# CBASS_AC_NONSAFE0_ISC register map
Vendor: Texas Instruments
Peripheral module from a debugger description file (folder J721S2).
Registers are 32-bit, read-write, reset 0x0 unless marked. A register's access mark holds for its fields unless they carry their own. Offsets are as the file gives them; lines under a group give offsets from that group; [hi:lo] are bit positions; {n}, {i} and the like mark numbered series; 'fields as' and 'values as' point back to an identical list; <NAME> marks a mode.

## CBASS_AC_NONSAFE0_ISC
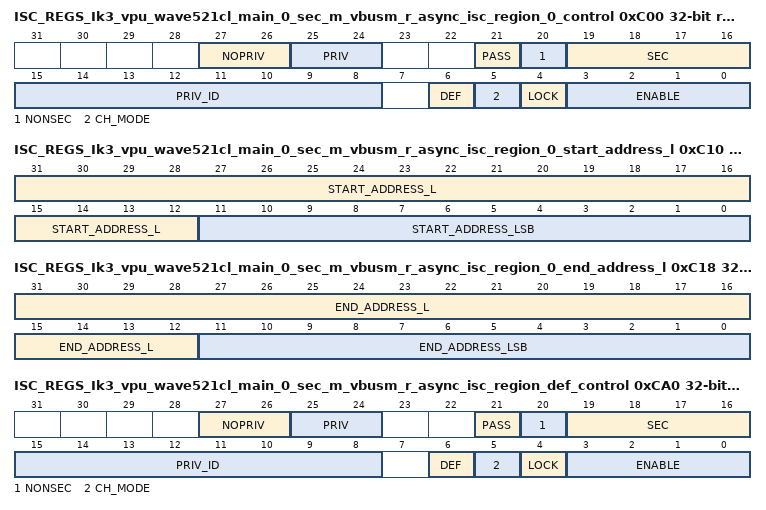
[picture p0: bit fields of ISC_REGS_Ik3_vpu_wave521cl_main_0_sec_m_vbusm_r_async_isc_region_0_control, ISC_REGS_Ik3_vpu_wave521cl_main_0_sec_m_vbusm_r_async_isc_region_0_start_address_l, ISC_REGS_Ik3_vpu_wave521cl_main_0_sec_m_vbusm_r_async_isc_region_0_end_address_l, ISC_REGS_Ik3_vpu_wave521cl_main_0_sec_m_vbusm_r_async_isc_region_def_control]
{0xC00+0x20*i} ISC_REGS_Ik3_vpu_wave521cl_main_0_sec_m_vbusm_r_async_isc_region_{i}_control access not given reset 0xBE00 (i=0..4) — The ISC Region {i} Control Register defines the control fields for the master Ik3_vpu_wave521cl_main_0.sec_m_vbusm_r_async region {i} ISC.
  [27:26] NOPRIV rw — Clear output priv attribute. If each bit is set then the outgoing priv bit is cleared.
  [25:24] PRIV rw — Set outgoing priv attribute. If each bit is set then the outgoing priv bit is set.
  [21] PASS rw — No privID replacement, pass through value.
  [20] NONSEC rw — Make outgoing non-secure.
  [19:16] SEC rw — Make outgoing secure. A value of 0xA enables, others disable.
  [15:8] PRIV_ID rw
  [6] DEF ro — Default region indication. The default region is used when all other regions do not match.
  [5] CH_MODE rw — Enable channel mode to match region to a chanid value. Otherwise use address mode to match region to an address range.
  [4] LOCK — Lock region. Once set the region values cannot be modified. (access R/W1TS)
  [3:0] ENABLE rw — Enable region. A value of 0xA enables, others disable.
{0xC10+0x20*i} ISC_REGS_Ik3_vpu_wave521cl_main_0_sec_m_vbusm_r_async_isc_region_{i}_start_address_l (i=0..4) — The ISC Region {i} Start Address Low Register defines the start address bits 31 to 0 for the master Ik3_vpu_wave521cl_main_0.sec_m_vbusm_r_async region {i} ISC.
  [31:12] START_ADDRESS_L — Start address bits 31 to 12.
  [11:0] START_ADDRESS_LSB — Start address bits 11 to 0 must be 0 as address must be 4KB aligned in address mode. Can also be channel number in channel mode.
{0xC14+0x20*i} ISC_REGS_Ik3_vpu_wave521cl_main_0_sec_m_vbusm_r_async_isc_region_{i}_start_address_h (i=0..4) — The ISC Region {i} Start Address High Register defines the start address bits 47 to 32 for the master Ik3_vpu_wave521cl_main_0.sec_m_vbusm_r_async region {i} ISC.
  [15:0] START_ADDRESS_H — Start address bits 47 to 32.
{0xC18+0x20*i} ISC_REGS_Ik3_vpu_wave521cl_main_0_sec_m_vbusm_r_async_isc_region_{i}_end_address_l access per field reset 0xFFF (i=0..4) — The ISC Region {i} End Address Low Register defines the end included address bits 31 to 0 for the master Ik3_vpu_wave521cl_main_0.sec_m_vbusm_r_async region {i} ISC.
  [31:12] END_ADDRESS_L rw — End address bits 31 to 12 to include in the match.
  [11:0] END_ADDRESS_LSB ro — End address bits 11 to 0 are forced to Fs as address must be 4KB aligned.
{0xC1C+0x20*i} ISC_REGS_Ik3_vpu_wave521cl_main_0_sec_m_vbusm_r_async_isc_region_{i}_end_address_h (i=0..4) — The ISC Region {i} End Address High Register defines the end address bits 47 to 32 for the master Ik3_vpu_wave521cl_main_0.sec_m_vbusm_r_async region {i} ISC.
  [15:0] END_ADDRESS_H — End address bits 47 to 32.
0xCA0 ISC_REGS_Ik3_vpu_wave521cl_main_0_sec_m_vbusm_r_async_isc_region_def_control access not given reset 0xBE4A — The ISC Default Region Control Register defines the control fields for the master Ik3_vpu_wave521cl_main_0.sec_m_vbusm_r_async region 5 ISC.
  [27:26] NOPRIV rw — Clear output priv attribute. If each bit is set then the outgoing priv bit is cleared, else the bit is unchanged. Do not set both priv and nopriv for the same bit.
  [25:24] PRIV rw — Set outgoing priv attribute. If each bit is set then the outgoing priv bit is set, else the bit is unchanged. Do not set both priv and nopriv for the same bit.
  [21] PASS rw — No privID replacement. A value of 1 will pass through privid value. A value of 0 will replace privid with priv_id field value.
  [20] NONSEC rw — Make outgoing non-secure. A value of 1 forces secure clear, others do nothing. Do not set both sec and nonsec.
  [19:16] SEC rw — Make outgoing secure. A value of 0xA forces secure set, others do nothing. Do not set both sec and nonsec.
  [15:8] PRIV_ID rw — Priv ID value to use if pass is 0.
  [6] DEF ro — Default region indication. The default region is used when all other regions do not match.
  [5] CH_MODE ro — Enable channel mode to match region to a chanid value. Otherwise use address mode to match region to an address range.
  [4] LOCK — Lock region. Once set, the region values cannot be modified. (access R/W1TS)
  [3:0] ENABLE ro — Enable region. A value of 0xA enables, others disable.
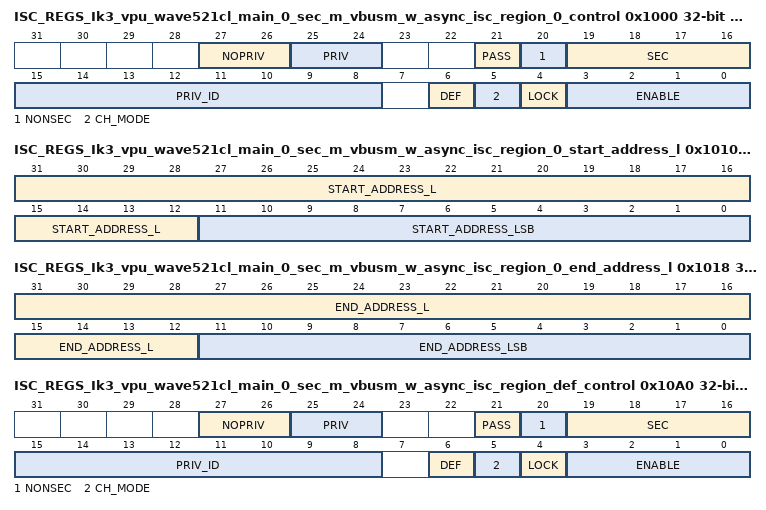
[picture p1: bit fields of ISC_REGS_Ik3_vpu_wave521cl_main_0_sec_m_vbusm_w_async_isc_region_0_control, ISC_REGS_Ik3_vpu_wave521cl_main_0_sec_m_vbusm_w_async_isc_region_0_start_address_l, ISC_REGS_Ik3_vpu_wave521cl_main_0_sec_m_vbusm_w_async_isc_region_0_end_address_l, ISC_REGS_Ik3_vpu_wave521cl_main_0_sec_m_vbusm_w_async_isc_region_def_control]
{0x1000+0x20*i} ISC_REGS_Ik3_vpu_wave521cl_main_0_sec_m_vbusm_w_async_isc_region_{i}_control access not given reset 0xBE00 (i=0..4) — The ISC Region {i} Control Register defines the control fields for the master Ik3_vpu_wave521cl_main_0.sec_m_vbusm_w_async region {i} ISC.
  fields as ISC_REGS_Ik3_vpu_wave521cl_main_0_sec_m_vbusm_r_async_isc_region_0_control
{0x1010+0x20*i} ISC_REGS_Ik3_vpu_wave521cl_main_0_sec_m_vbusm_w_async_isc_region_{i}_start_address_l (i=0..4) — The ISC Region {i} Start Address Low Register defines the start address bits 31 to 0 for the master Ik3_vpu_wave521cl_main_0.sec_m_vbusm_w_async region {i} ISC.
  fields as ISC_REGS_Ik3_vpu_wave521cl_main_0_sec_m_vbusm_r_async_isc_region_0_start_address_l
{0x1014+0x20*i} ISC_REGS_Ik3_vpu_wave521cl_main_0_sec_m_vbusm_w_async_isc_region_{i}_start_address_h (i=0..4) — The ISC Region {i} Start Address High Register defines the start address bits 47 to 32 for the master Ik3_vpu_wave521cl_main_0.sec_m_vbusm_w_async region {i} ISC.
  [15:0] START_ADDRESS_H — Start address bits 47 to 32.
{0x1018+0x20*i} ISC_REGS_Ik3_vpu_wave521cl_main_0_sec_m_vbusm_w_async_isc_region_{i}_end_address_l access per field reset 0xFFF (i=0..4) — The ISC Region {i} End Address Low Register defines the end included address bits 31 to 0 for the master Ik3_vpu_wave521cl_main_0.sec_m_vbusm_w_async region {i} ISC.
  fields as ISC_REGS_Ik3_vpu_wave521cl_main_0_sec_m_vbusm_r_async_isc_region_0_end_address_l
{0x101C+0x20*i} ISC_REGS_Ik3_vpu_wave521cl_main_0_sec_m_vbusm_w_async_isc_region_{i}_end_address_h (i=0..4) — The ISC Region {i} End Address High Register defines the end address bits 47 to 32 for the master Ik3_vpu_wave521cl_main_0.sec_m_vbusm_w_async region {i} ISC.
  [15:0] END_ADDRESS_H — End address bits 47 to 32.
0x10A0 ISC_REGS_Ik3_vpu_wave521cl_main_0_sec_m_vbusm_w_async_isc_region_def_control access not given reset 0xBE4A — The ISC Default Region Control Register defines the control fields for the master Ik3_vpu_wave521cl_main_0.sec_m_vbusm_w_async region 5 ISC.
  fields as ISC_REGS_Ik3_vpu_wave521cl_main_0_sec_m_vbusm_r_async_isc_region_def_control
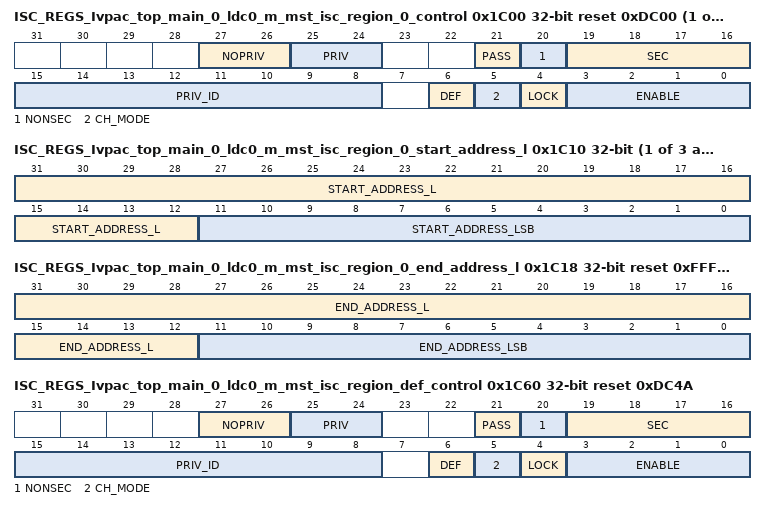
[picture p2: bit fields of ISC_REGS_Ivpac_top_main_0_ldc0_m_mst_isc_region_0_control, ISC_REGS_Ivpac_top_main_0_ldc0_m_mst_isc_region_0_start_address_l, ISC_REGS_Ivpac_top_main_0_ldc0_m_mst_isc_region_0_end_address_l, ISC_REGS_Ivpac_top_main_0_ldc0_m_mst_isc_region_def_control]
{0x1C00+0x20*i} ISC_REGS_Ivpac_top_main_0_ldc0_m_mst_isc_region_{i}_control access not given reset 0xDC00 (i=0..2) — The ISC Region {i} Control Register defines the control fields for the master Ivpac_top_main_0.ldc0_m_mst region {i} ISC.
  fields as ISC_REGS_Ik3_vpu_wave521cl_main_0_sec_m_vbusm_r_async_isc_region_0_control
{0x1C10+0x20*i} ISC_REGS_Ivpac_top_main_0_ldc0_m_mst_isc_region_{i}_start_address_l (i=0..2) — The ISC Region {i} Start Address Low Register defines the start address bits 31 to 0 for the master Ivpac_top_main_0.ldc0_m_mst region {i} ISC.
  fields as ISC_REGS_Ik3_vpu_wave521cl_main_0_sec_m_vbusm_r_async_isc_region_0_start_address_l
{0x1C14+0x20*i} ISC_REGS_Ivpac_top_main_0_ldc0_m_mst_isc_region_{i}_start_address_h (i=0..2) — The ISC Region {i} Start Address High Register defines the start address bits 47 to 32 for the master Ivpac_top_main_0.ldc0_m_mst region {i} ISC.
  [15:0] START_ADDRESS_H — Start address bits 47 to 32.
{0x1C18+0x20*i} ISC_REGS_Ivpac_top_main_0_ldc0_m_mst_isc_region_{i}_end_address_l access per field reset 0xFFF (i=0..2) — The ISC Region {i} End Address Low Register defines the end included address bits 31 to 0 for the master Ivpac_top_main_0.ldc0_m_mst region {i} ISC.
  fields as ISC_REGS_Ik3_vpu_wave521cl_main_0_sec_m_vbusm_r_async_isc_region_0_end_address_l
{0x1C1C+0x20*i} ISC_REGS_Ivpac_top_main_0_ldc0_m_mst_isc_region_{i}_end_address_h (i=0..2) — The ISC Region {i} End Address High Register defines the end address bits 47 to 32 for the master Ivpac_top_main_0.ldc0_m_mst region {i} ISC.
  [15:0] END_ADDRESS_H — End address bits 47 to 32.
0x1C60 ISC_REGS_Ivpac_top_main_0_ldc0_m_mst_isc_region_def_control access not given reset 0xDC4A — The ISC Default Region Control Register defines the control fields for the master Ivpac_top_main_0.ldc0_m_mst region 3 ISC.
  fields as ISC_REGS_Ik3_vpu_wave521cl_main_0_sec_m_vbusm_r_async_isc_region_def_control
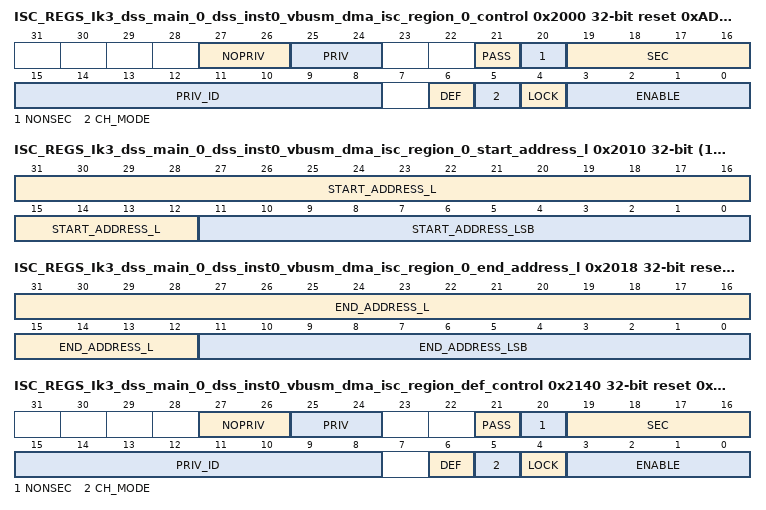
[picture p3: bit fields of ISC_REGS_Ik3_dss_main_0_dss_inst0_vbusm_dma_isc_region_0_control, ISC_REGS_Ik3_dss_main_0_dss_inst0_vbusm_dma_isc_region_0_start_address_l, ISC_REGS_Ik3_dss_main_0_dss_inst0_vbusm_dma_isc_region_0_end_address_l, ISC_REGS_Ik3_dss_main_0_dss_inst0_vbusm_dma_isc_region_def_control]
{0x2000+0x20*i} ISC_REGS_Ik3_dss_main_0_dss_inst0_vbusm_dma_isc_region_{i}_control access not given reset 0xAD00 (i=0..9) — The ISC Region {i} Control Register defines the control fields for the master Ik3_dss_main_0.dss_inst0_vbusm_dma region {i} ISC.
  fields as ISC_REGS_Ik3_vpu_wave521cl_main_0_sec_m_vbusm_r_async_isc_region_0_control
{0x2010+0x20*i} ISC_REGS_Ik3_dss_main_0_dss_inst0_vbusm_dma_isc_region_{i}_start_address_l (i=0..9) — The ISC Region {i} Start Address Low Register defines the start address bits 31 to 0 for the master Ik3_dss_main_0.dss_inst0_vbusm_dma region {i} ISC.
  fields as ISC_REGS_Ik3_vpu_wave521cl_main_0_sec_m_vbusm_r_async_isc_region_0_start_address_l
{0x2014+0x20*i} ISC_REGS_Ik3_dss_main_0_dss_inst0_vbusm_dma_isc_region_{i}_start_address_h (i=0..9) — The ISC Region {i} Start Address High Register defines the start address bits 47 to 32 for the master Ik3_dss_main_0.dss_inst0_vbusm_dma region {i} ISC.
  [15:0] START_ADDRESS_H — Start address bits 47 to 32.
{0x2018+0x20*i} ISC_REGS_Ik3_dss_main_0_dss_inst0_vbusm_dma_isc_region_{i}_end_address_l access per field reset 0xFFF (i=0..9) — The ISC Region {i} End Address Low Register defines the end included address bits 31 to 0 for the master Ik3_dss_main_0.dss_inst0_vbusm_dma region {i} ISC.
  fields as ISC_REGS_Ik3_vpu_wave521cl_main_0_sec_m_vbusm_r_async_isc_region_0_end_address_l
{0x201C+0x20*i} ISC_REGS_Ik3_dss_main_0_dss_inst0_vbusm_dma_isc_region_{i}_end_address_h (i=0..9) — The ISC Region {i} End Address High Register defines the end address bits 47 to 32 for the master Ik3_dss_main_0.dss_inst0_vbusm_dma region {i} ISC.
  [15:0] END_ADDRESS_H — End address bits 47 to 32.
0x2140 ISC_REGS_Ik3_dss_main_0_dss_inst0_vbusm_dma_isc_region_def_control access not given reset 0xAD4A — The ISC Default Region Control Register defines the control fields for the master Ik3_dss_main_0.dss_inst0_vbusm_dma region 10 ISC.
  fields as ISC_REGS_Ik3_vpu_wave521cl_main_0_sec_m_vbusm_r_async_isc_region_def_control
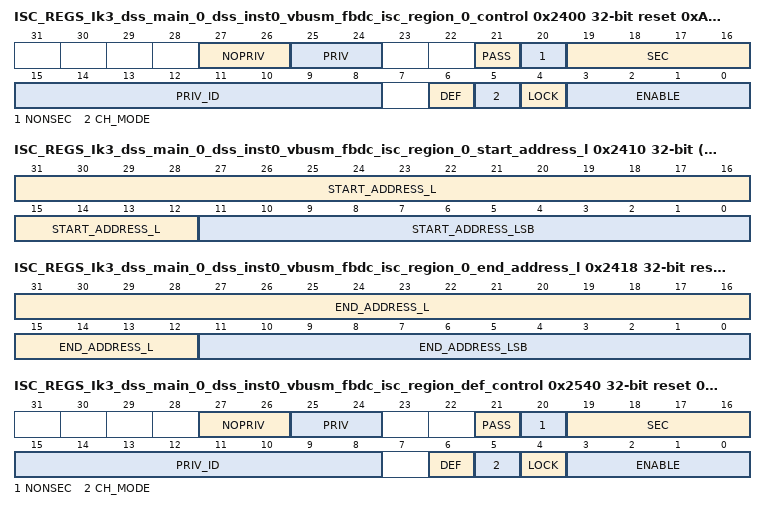
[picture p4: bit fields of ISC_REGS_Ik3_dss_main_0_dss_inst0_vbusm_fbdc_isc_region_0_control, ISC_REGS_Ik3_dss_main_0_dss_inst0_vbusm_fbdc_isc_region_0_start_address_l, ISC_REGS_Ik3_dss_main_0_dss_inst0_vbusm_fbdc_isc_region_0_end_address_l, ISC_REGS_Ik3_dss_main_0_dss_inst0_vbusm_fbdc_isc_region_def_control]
{0x2400+0x20*i} ISC_REGS_Ik3_dss_main_0_dss_inst0_vbusm_fbdc_isc_region_{i}_control access not given reset 0xAD00 (i=0..9) — The ISC Region {i} Control Register defines the control fields for the master Ik3_dss_main_0.dss_inst0_vbusm_fbdc region {i} ISC.
  fields as ISC_REGS_Ik3_vpu_wave521cl_main_0_sec_m_vbusm_r_async_isc_region_0_control
{0x2410+0x20*i} ISC_REGS_Ik3_dss_main_0_dss_inst0_vbusm_fbdc_isc_region_{i}_start_address_l (i=0..9) — The ISC Region {i} Start Address Low Register defines the start address bits 31 to 0 for the master Ik3_dss_main_0.dss_inst0_vbusm_fbdc region {i} ISC.
  fields as ISC_REGS_Ik3_vpu_wave521cl_main_0_sec_m_vbusm_r_async_isc_region_0_start_address_l
{0x2414+0x20*i} ISC_REGS_Ik3_dss_main_0_dss_inst0_vbusm_fbdc_isc_region_{i}_start_address_h (i=0..9) — The ISC Region {i} Start Address High Register defines the start address bits 47 to 32 for the master Ik3_dss_main_0.dss_inst0_vbusm_fbdc region {i} ISC.
  [15:0] START_ADDRESS_H — Start address bits 47 to 32.
{0x2418+0x20*i} ISC_REGS_Ik3_dss_main_0_dss_inst0_vbusm_fbdc_isc_region_{i}_end_address_l access per field reset 0xFFF (i=0..9) — The ISC Region {i} End Address Low Register defines the end included address bits 31 to 0 for the master Ik3_dss_main_0.dss_inst0_vbusm_fbdc region {i} ISC.
  fields as ISC_REGS_Ik3_vpu_wave521cl_main_0_sec_m_vbusm_r_async_isc_region_0_end_address_l
{0x241C+0x20*i} ISC_REGS_Ik3_dss_main_0_dss_inst0_vbusm_fbdc_isc_region_{i}_end_address_h (i=0..9) — The ISC Region {i} End Address High Register defines the end address bits 47 to 32 for the master Ik3_dss_main_0.dss_inst0_vbusm_fbdc region {i} ISC.
  [15:0] END_ADDRESS_H — End address bits 47 to 32.
0x2540 ISC_REGS_Ik3_dss_main_0_dss_inst0_vbusm_fbdc_isc_region_def_control access not given reset 0xAD4A — The ISC Default Region Control Register defines the control fields for the master Ik3_dss_main_0.dss_inst0_vbusm_fbdc region 10 ISC.
  fields as ISC_REGS_Ik3_vpu_wave521cl_main_0_sec_m_vbusm_r_async_isc_region_def_control
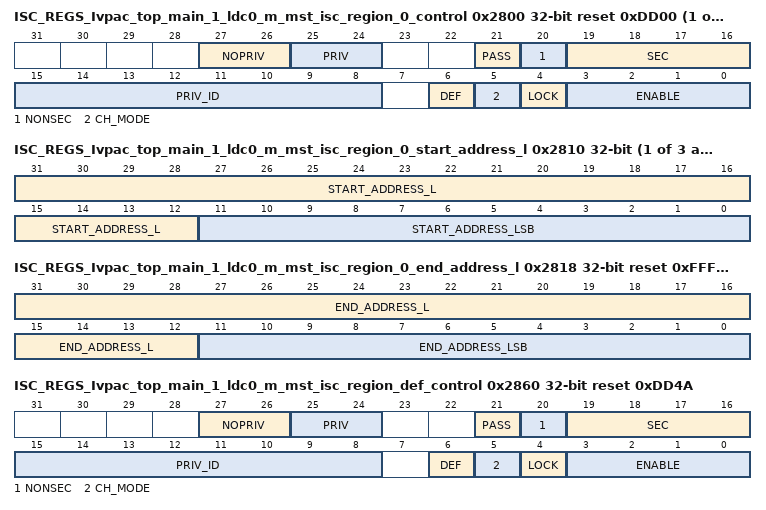
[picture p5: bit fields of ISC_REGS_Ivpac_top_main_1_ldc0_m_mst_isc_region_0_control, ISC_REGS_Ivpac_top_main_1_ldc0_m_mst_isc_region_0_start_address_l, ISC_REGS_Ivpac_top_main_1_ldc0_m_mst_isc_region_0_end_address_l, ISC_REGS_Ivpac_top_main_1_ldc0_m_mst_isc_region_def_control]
{0x2800+0x20*i} ISC_REGS_Ivpac_top_main_1_ldc0_m_mst_isc_region_{i}_control access not given reset 0xDD00 (i=0..2) — The ISC Region {i} Control Register defines the control fields for the master Ivpac_top_main_1.ldc0_m_mst region {i} ISC.
  fields as ISC_REGS_Ik3_vpu_wave521cl_main_0_sec_m_vbusm_r_async_isc_region_0_control
{0x2810+0x20*i} ISC_REGS_Ivpac_top_main_1_ldc0_m_mst_isc_region_{i}_start_address_l (i=0..2) — The ISC Region {i} Start Address Low Register defines the start address bits 31 to 0 for the master Ivpac_top_main_1.ldc0_m_mst region {i} ISC.
  fields as ISC_REGS_Ik3_vpu_wave521cl_main_0_sec_m_vbusm_r_async_isc_region_0_start_address_l
{0x2814+0x20*i} ISC_REGS_Ivpac_top_main_1_ldc0_m_mst_isc_region_{i}_start_address_h (i=0..2) — The ISC Region {i} Start Address High Register defines the start address bits 47 to 32 for the master Ivpac_top_main_1.ldc0_m_mst region {i} ISC.
  [15:0] START_ADDRESS_H — Start address bits 47 to 32.
{0x2818+0x20*i} ISC_REGS_Ivpac_top_main_1_ldc0_m_mst_isc_region_{i}_end_address_l access per field reset 0xFFF (i=0..2) — The ISC Region {i} End Address Low Register defines the end included address bits 31 to 0 for the master Ivpac_top_main_1.ldc0_m_mst region {i} ISC.
  fields as ISC_REGS_Ik3_vpu_wave521cl_main_0_sec_m_vbusm_r_async_isc_region_0_end_address_l
{0x281C+0x20*i} ISC_REGS_Ivpac_top_main_1_ldc0_m_mst_isc_region_{i}_end_address_h (i=0..2) — The ISC Region {i} End Address High Register defines the end address bits 47 to 32 for the master Ivpac_top_main_1.ldc0_m_mst region {i} ISC.
  [15:0] END_ADDRESS_H — End address bits 47 to 32.
0x2860 ISC_REGS_Ivpac_top_main_1_ldc0_m_mst_isc_region_def_control access not given reset 0xDD4A — The ISC Default Region Control Register defines the control fields for the master Ivpac_top_main_1.ldc0_m_mst region 3 ISC.
  fields as ISC_REGS_Ik3_vpu_wave521cl_main_0_sec_m_vbusm_r_async_isc_region_def_control
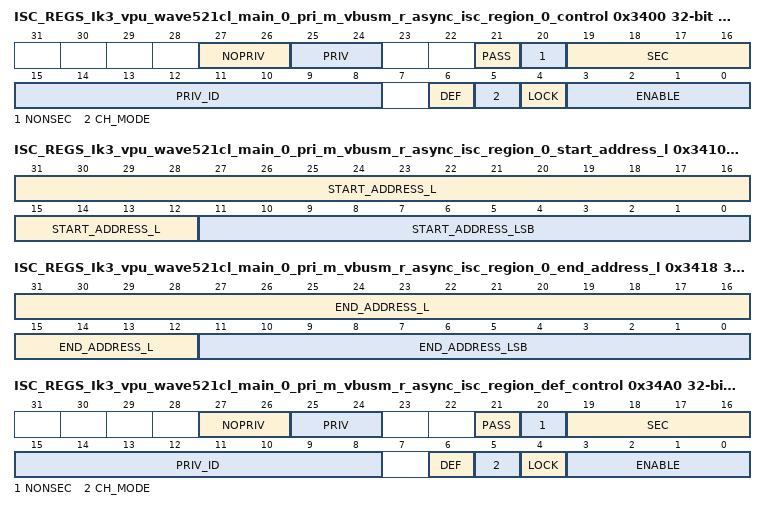
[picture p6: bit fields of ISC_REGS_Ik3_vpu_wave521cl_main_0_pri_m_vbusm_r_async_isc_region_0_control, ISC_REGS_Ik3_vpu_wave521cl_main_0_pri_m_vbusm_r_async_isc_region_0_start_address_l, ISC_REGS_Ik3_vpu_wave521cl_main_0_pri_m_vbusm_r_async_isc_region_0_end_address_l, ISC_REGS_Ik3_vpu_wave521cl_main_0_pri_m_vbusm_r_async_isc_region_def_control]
{0x3400+0x20*i} ISC_REGS_Ik3_vpu_wave521cl_main_0_pri_m_vbusm_r_async_isc_region_{i}_control access not given reset 0xBE00 (i=0..4) — The ISC Region {i} Control Register defines the control fields for the master Ik3_vpu_wave521cl_main_0.pri_m_vbusm_r_async region {i} ISC.
  fields as ISC_REGS_Ik3_vpu_wave521cl_main_0_sec_m_vbusm_r_async_isc_region_0_control
{0x3410+0x20*i} ISC_REGS_Ik3_vpu_wave521cl_main_0_pri_m_vbusm_r_async_isc_region_{i}_start_address_l (i=0..4) — The ISC Region {i} Start Address Low Register defines the start address bits 31 to 0 for the master Ik3_vpu_wave521cl_main_0.pri_m_vbusm_r_async region {i} ISC.
  fields as ISC_REGS_Ik3_vpu_wave521cl_main_0_sec_m_vbusm_r_async_isc_region_0_start_address_l
{0x3414+0x20*i} ISC_REGS_Ik3_vpu_wave521cl_main_0_pri_m_vbusm_r_async_isc_region_{i}_start_address_h (i=0..4) — The ISC Region {i} Start Address High Register defines the start address bits 47 to 32 for the master Ik3_vpu_wave521cl_main_0.pri_m_vbusm_r_async region {i} ISC.
  [15:0] START_ADDRESS_H — Start address bits 47 to 32.
{0x3418+0x20*i} ISC_REGS_Ik3_vpu_wave521cl_main_0_pri_m_vbusm_r_async_isc_region_{i}_end_address_l access per field reset 0xFFF (i=0..4) — The ISC Region {i} End Address Low Register defines the end included address bits 31 to 0 for the master Ik3_vpu_wave521cl_main_0.pri_m_vbusm_r_async region {i} ISC.
  fields as ISC_REGS_Ik3_vpu_wave521cl_main_0_sec_m_vbusm_r_async_isc_region_0_end_address_l
{0x341C+0x20*i} ISC_REGS_Ik3_vpu_wave521cl_main_0_pri_m_vbusm_r_async_isc_region_{i}_end_address_h (i=0..4) — The ISC Region {i} End Address High Register defines the end address bits 47 to 32 for the master Ik3_vpu_wave521cl_main_0.pri_m_vbusm_r_async region {i} ISC.
  [15:0] END_ADDRESS_H — End address bits 47 to 32.
0x34A0 ISC_REGS_Ik3_vpu_wave521cl_main_0_pri_m_vbusm_r_async_isc_region_def_control access not given reset 0xBE4A — The ISC Default Region Control Register defines the control fields for the master Ik3_vpu_wave521cl_main_0.pri_m_vbusm_r_async region 5 ISC.
  fields as ISC_REGS_Ik3_vpu_wave521cl_main_0_sec_m_vbusm_r_async_isc_region_def_control
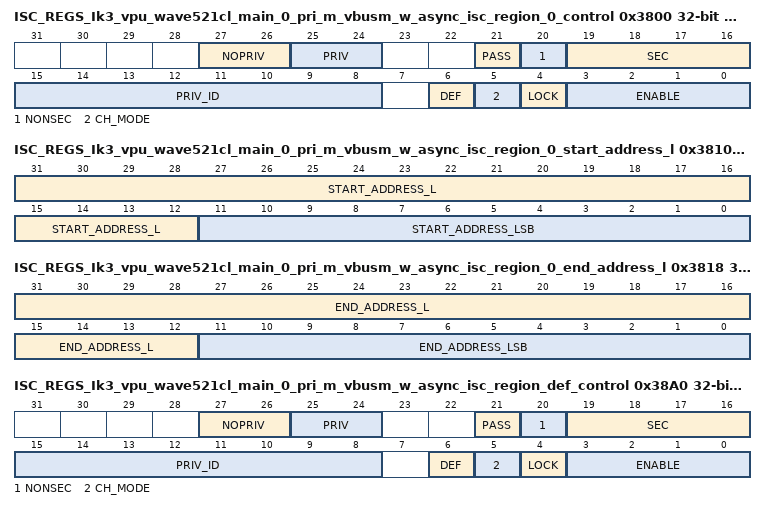
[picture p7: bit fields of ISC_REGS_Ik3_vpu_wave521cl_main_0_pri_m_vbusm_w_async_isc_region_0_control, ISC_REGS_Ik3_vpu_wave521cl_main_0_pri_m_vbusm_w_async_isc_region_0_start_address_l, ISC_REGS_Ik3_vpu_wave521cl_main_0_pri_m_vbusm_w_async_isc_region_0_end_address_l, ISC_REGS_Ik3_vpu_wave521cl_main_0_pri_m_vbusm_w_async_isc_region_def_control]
{0x3800+0x20*i} ISC_REGS_Ik3_vpu_wave521cl_main_0_pri_m_vbusm_w_async_isc_region_{i}_control access not given reset 0xBE00 (i=0..4) — The ISC Region {i} Control Register defines the control fields for the master Ik3_vpu_wave521cl_main_0.pri_m_vbusm_w_async region {i} ISC.
  fields as ISC_REGS_Ik3_vpu_wave521cl_main_0_sec_m_vbusm_r_async_isc_region_0_control
{0x3810+0x20*i} ISC_REGS_Ik3_vpu_wave521cl_main_0_pri_m_vbusm_w_async_isc_region_{i}_start_address_l (i=0..4) — The ISC Region {i} Start Address Low Register defines the start address bits 31 to 0 for the master Ik3_vpu_wave521cl_main_0.pri_m_vbusm_w_async region {i} ISC.
  fields as ISC_REGS_Ik3_vpu_wave521cl_main_0_sec_m_vbusm_r_async_isc_region_0_start_address_l
{0x3814+0x20*i} ISC_REGS_Ik3_vpu_wave521cl_main_0_pri_m_vbusm_w_async_isc_region_{i}_start_address_h (i=0..4) — The ISC Region {i} Start Address High Register defines the start address bits 47 to 32 for the master Ik3_vpu_wave521cl_main_0.pri_m_vbusm_w_async region {i} ISC.
  [15:0] START_ADDRESS_H — Start address bits 47 to 32.
{0x3818+0x20*i} ISC_REGS_Ik3_vpu_wave521cl_main_0_pri_m_vbusm_w_async_isc_region_{i}_end_address_l access per field reset 0xFFF (i=0..4) — The ISC Region {i} End Address Low Register defines the end included address bits 31 to 0 for the master Ik3_vpu_wave521cl_main_0.pri_m_vbusm_w_async region {i} ISC.
  fields as ISC_REGS_Ik3_vpu_wave521cl_main_0_sec_m_vbusm_r_async_isc_region_0_end_address_l
{0x381C+0x20*i} ISC_REGS_Ik3_vpu_wave521cl_main_0_pri_m_vbusm_w_async_isc_region_{i}_end_address_h (i=0..4) — The ISC Region {i} End Address High Register defines the end address bits 47 to 32 for the master Ik3_vpu_wave521cl_main_0.pri_m_vbusm_w_async region {i} ISC.
  [15:0] END_ADDRESS_H — End address bits 47 to 32.
0x38A0 ISC_REGS_Ik3_vpu_wave521cl_main_0_pri_m_vbusm_w_async_isc_region_def_control access not given reset 0xBE4A — The ISC Default Region Control Register defines the control fields for the master Ik3_vpu_wave521cl_main_0.pri_m_vbusm_w_async region 5 ISC.
  fields as ISC_REGS_Ik3_vpu_wave521cl_main_0_sec_m_vbusm_r_async_isc_region_def_control
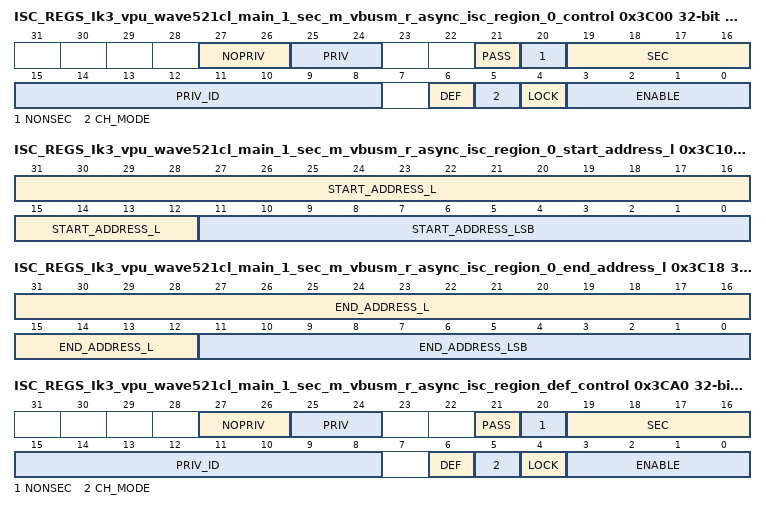
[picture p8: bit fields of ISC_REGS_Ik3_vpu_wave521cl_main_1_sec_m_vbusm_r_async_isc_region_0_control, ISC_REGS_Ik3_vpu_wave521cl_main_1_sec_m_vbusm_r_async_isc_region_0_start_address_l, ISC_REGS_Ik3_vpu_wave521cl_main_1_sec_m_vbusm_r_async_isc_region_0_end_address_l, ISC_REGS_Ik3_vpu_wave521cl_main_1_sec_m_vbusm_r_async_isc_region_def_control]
{0x3C00+0x20*i} ISC_REGS_Ik3_vpu_wave521cl_main_1_sec_m_vbusm_r_async_isc_region_{i}_control access not given reset 0xBF00 (i=0..4) — The ISC Region {i} Control Register defines the control fields for the master Ik3_vpu_wave521cl_main_1.sec_m_vbusm_r_async region {i} ISC.
  fields as ISC_REGS_Ik3_vpu_wave521cl_main_0_sec_m_vbusm_r_async_isc_region_0_control
{0x3C10+0x20*i} ISC_REGS_Ik3_vpu_wave521cl_main_1_sec_m_vbusm_r_async_isc_region_{i}_start_address_l (i=0..4) — The ISC Region {i} Start Address Low Register defines the start address bits 31 to 0 for the master Ik3_vpu_wave521cl_main_1.sec_m_vbusm_r_async region {i} ISC.
  fields as ISC_REGS_Ik3_vpu_wave521cl_main_0_sec_m_vbusm_r_async_isc_region_0_start_address_l
{0x3C14+0x20*i} ISC_REGS_Ik3_vpu_wave521cl_main_1_sec_m_vbusm_r_async_isc_region_{i}_start_address_h (i=0..4) — The ISC Region {i} Start Address High Register defines the start address bits 47 to 32 for the master Ik3_vpu_wave521cl_main_1.sec_m_vbusm_r_async region {i} ISC.
  [15:0] START_ADDRESS_H — Start address bits 47 to 32.
{0x3C18+0x20*i} ISC_REGS_Ik3_vpu_wave521cl_main_1_sec_m_vbusm_r_async_isc_region_{i}_end_address_l access per field reset 0xFFF (i=0..4) — The ISC Region {i} End Address Low Register defines the end included address bits 31 to 0 for the master Ik3_vpu_wave521cl_main_1.sec_m_vbusm_r_async region {i} ISC.
  fields as ISC_REGS_Ik3_vpu_wave521cl_main_0_sec_m_vbusm_r_async_isc_region_0_end_address_l
{0x3C1C+0x20*i} ISC_REGS_Ik3_vpu_wave521cl_main_1_sec_m_vbusm_r_async_isc_region_{i}_end_address_h (i=0..4) — The ISC Region {i} End Address High Register defines the end address bits 47 to 32 for the master Ik3_vpu_wave521cl_main_1.sec_m_vbusm_r_async region {i} ISC.
  [15:0] END_ADDRESS_H — End address bits 47 to 32.
0x3CA0 ISC_REGS_Ik3_vpu_wave521cl_main_1_sec_m_vbusm_r_async_isc_region_def_control access not given reset 0xBF4A — The ISC Default Region Control Register defines the control fields for the master Ik3_vpu_wave521cl_main_1.sec_m_vbusm_r_async region 5 ISC.
  fields as ISC_REGS_Ik3_vpu_wave521cl_main_0_sec_m_vbusm_r_async_isc_region_def_control
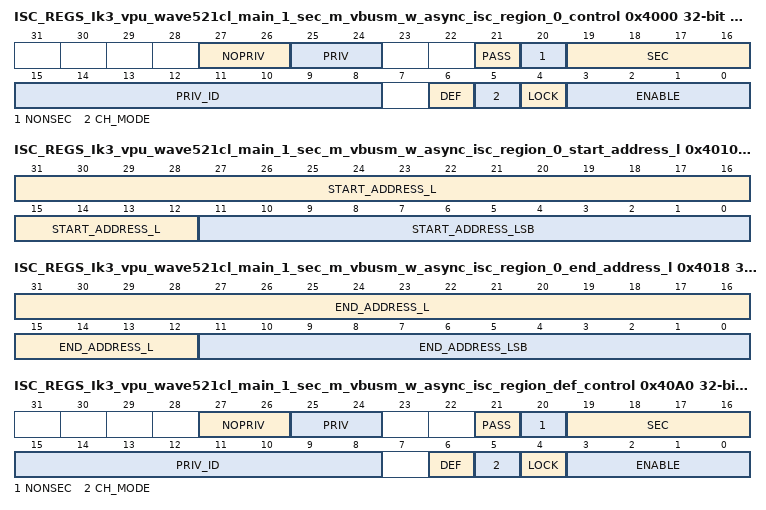
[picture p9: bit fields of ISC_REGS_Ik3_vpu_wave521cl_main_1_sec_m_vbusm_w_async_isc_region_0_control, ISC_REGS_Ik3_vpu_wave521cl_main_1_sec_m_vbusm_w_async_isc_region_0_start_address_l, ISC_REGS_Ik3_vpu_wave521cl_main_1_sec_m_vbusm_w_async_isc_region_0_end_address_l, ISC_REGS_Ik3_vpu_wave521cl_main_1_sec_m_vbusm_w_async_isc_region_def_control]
{0x4000+0x20*i} ISC_REGS_Ik3_vpu_wave521cl_main_1_sec_m_vbusm_w_async_isc_region_{i}_control access not given reset 0xBF00 (i=0..4) — The ISC Region {i} Control Register defines the control fields for the master Ik3_vpu_wave521cl_main_1.sec_m_vbusm_w_async region {i} ISC.
  fields as ISC_REGS_Ik3_vpu_wave521cl_main_0_sec_m_vbusm_r_async_isc_region_0_control
{0x4010+0x20*i} ISC_REGS_Ik3_vpu_wave521cl_main_1_sec_m_vbusm_w_async_isc_region_{i}_start_address_l (i=0..4) — The ISC Region {i} Start Address Low Register defines the start address bits 31 to 0 for the master Ik3_vpu_wave521cl_main_1.sec_m_vbusm_w_async region {i} ISC.
  fields as ISC_REGS_Ik3_vpu_wave521cl_main_0_sec_m_vbusm_r_async_isc_region_0_start_address_l
{0x4014+0x20*i} ISC_REGS_Ik3_vpu_wave521cl_main_1_sec_m_vbusm_w_async_isc_region_{i}_start_address_h (i=0..4) — The ISC Region {i} Start Address High Register defines the start address bits 47 to 32 for the master Ik3_vpu_wave521cl_main_1.sec_m_vbusm_w_async region {i} ISC.
  [15:0] START_ADDRESS_H — Start address bits 47 to 32.
{0x4018+0x20*i} ISC_REGS_Ik3_vpu_wave521cl_main_1_sec_m_vbusm_w_async_isc_region_{i}_end_address_l access per field reset 0xFFF (i=0..4) — The ISC Region {i} End Address Low Register defines the end included address bits 31 to 0 for the master Ik3_vpu_wave521cl_main_1.sec_m_vbusm_w_async region {i} ISC.
  fields as ISC_REGS_Ik3_vpu_wave521cl_main_0_sec_m_vbusm_r_async_isc_region_0_end_address_l
{0x401C+0x20*i} ISC_REGS_Ik3_vpu_wave521cl_main_1_sec_m_vbusm_w_async_isc_region_{i}_end_address_h (i=0..4) — The ISC Region {i} End Address High Register defines the end address bits 47 to 32 for the master Ik3_vpu_wave521cl_main_1.sec_m_vbusm_w_async region {i} ISC.
  [15:0] END_ADDRESS_H — End address bits 47 to 32.
0x40A0 ISC_REGS_Ik3_vpu_wave521cl_main_1_sec_m_vbusm_w_async_isc_region_def_control access not given reset 0xBF4A — The ISC Default Region Control Register defines the control fields for the master Ik3_vpu_wave521cl_main_1.sec_m_vbusm_w_async region 5 ISC.
  fields as ISC_REGS_Ik3_vpu_wave521cl_main_0_sec_m_vbusm_r_async_isc_region_def_control
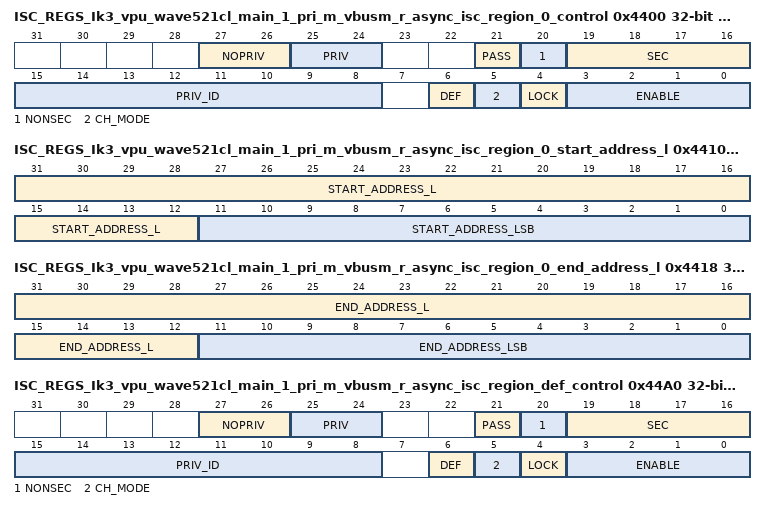
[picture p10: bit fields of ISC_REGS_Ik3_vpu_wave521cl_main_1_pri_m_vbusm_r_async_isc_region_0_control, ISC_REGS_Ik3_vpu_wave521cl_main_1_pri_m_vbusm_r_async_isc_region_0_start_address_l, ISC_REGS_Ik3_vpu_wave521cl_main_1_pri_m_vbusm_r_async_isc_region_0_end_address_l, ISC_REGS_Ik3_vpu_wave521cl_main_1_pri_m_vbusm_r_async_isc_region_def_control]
{0x4400+0x20*i} ISC_REGS_Ik3_vpu_wave521cl_main_1_pri_m_vbusm_r_async_isc_region_{i}_control access not given reset 0xBF00 (i=0..4) — The ISC Region {i} Control Register defines the control fields for the master Ik3_vpu_wave521cl_main_1.pri_m_vbusm_r_async region {i} ISC.
  fields as ISC_REGS_Ik3_vpu_wave521cl_main_0_sec_m_vbusm_r_async_isc_region_0_control
{0x4410+0x20*i} ISC_REGS_Ik3_vpu_wave521cl_main_1_pri_m_vbusm_r_async_isc_region_{i}_start_address_l (i=0..4) — The ISC Region {i} Start Address Low Register defines the start address bits 31 to 0 for the master Ik3_vpu_wave521cl_main_1.pri_m_vbusm_r_async region {i} ISC.
  fields as ISC_REGS_Ik3_vpu_wave521cl_main_0_sec_m_vbusm_r_async_isc_region_0_start_address_l
{0x4414+0x20*i} ISC_REGS_Ik3_vpu_wave521cl_main_1_pri_m_vbusm_r_async_isc_region_{i}_start_address_h (i=0..4) — The ISC Region {i} Start Address High Register defines the start address bits 47 to 32 for the master Ik3_vpu_wave521cl_main_1.pri_m_vbusm_r_async region {i} ISC.
  [15:0] START_ADDRESS_H — Start address bits 47 to 32.
{0x4418+0x20*i} ISC_REGS_Ik3_vpu_wave521cl_main_1_pri_m_vbusm_r_async_isc_region_{i}_end_address_l access per field reset 0xFFF (i=0..4) — The ISC Region {i} End Address Low Register defines the end included address bits 31 to 0 for the master Ik3_vpu_wave521cl_main_1.pri_m_vbusm_r_async region {i} ISC.
  fields as ISC_REGS_Ik3_vpu_wave521cl_main_0_sec_m_vbusm_r_async_isc_region_0_end_address_l
{0x441C+0x20*i} ISC_REGS_Ik3_vpu_wave521cl_main_1_pri_m_vbusm_r_async_isc_region_{i}_end_address_h (i=0..4) — The ISC Region {i} End Address High Register defines the end address bits 47 to 32 for the master Ik3_vpu_wave521cl_main_1.pri_m_vbusm_r_async region {i} ISC.
  [15:0] END_ADDRESS_H — End address bits 47 to 32.
0x44A0 ISC_REGS_Ik3_vpu_wave521cl_main_1_pri_m_vbusm_r_async_isc_region_def_control access not given reset 0xBF4A — The ISC Default Region Control Register defines the control fields for the master Ik3_vpu_wave521cl_main_1.pri_m_vbusm_r_async region 5 ISC.
  fields as ISC_REGS_Ik3_vpu_wave521cl_main_0_sec_m_vbusm_r_async_isc_region_def_control
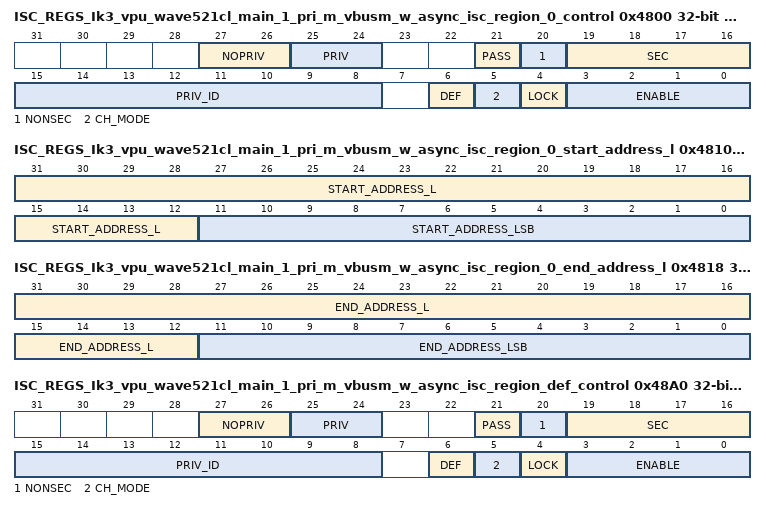
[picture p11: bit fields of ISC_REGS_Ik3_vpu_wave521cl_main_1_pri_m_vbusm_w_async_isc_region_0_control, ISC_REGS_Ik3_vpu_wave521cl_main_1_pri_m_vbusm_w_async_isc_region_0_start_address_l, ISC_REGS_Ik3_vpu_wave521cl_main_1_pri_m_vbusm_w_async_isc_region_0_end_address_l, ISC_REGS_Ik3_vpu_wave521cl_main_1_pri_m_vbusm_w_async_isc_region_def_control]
{0x4800+0x20*i} ISC_REGS_Ik3_vpu_wave521cl_main_1_pri_m_vbusm_w_async_isc_region_{i}_control access not given reset 0xBF00 (i=0..4) — The ISC Region {i} Control Register defines the control fields for the master Ik3_vpu_wave521cl_main_1.pri_m_vbusm_w_async region {i} ISC.
  fields as ISC_REGS_Ik3_vpu_wave521cl_main_0_sec_m_vbusm_r_async_isc_region_0_control
{0x4810+0x20*i} ISC_REGS_Ik3_vpu_wave521cl_main_1_pri_m_vbusm_w_async_isc_region_{i}_start_address_l (i=0..4) — The ISC Region {i} Start Address Low Register defines the start address bits 31 to 0 for the master Ik3_vpu_wave521cl_main_1.pri_m_vbusm_w_async region {i} ISC.
  fields as ISC_REGS_Ik3_vpu_wave521cl_main_0_sec_m_vbusm_r_async_isc_region_0_start_address_l
{0x4814+0x20*i} ISC_REGS_Ik3_vpu_wave521cl_main_1_pri_m_vbusm_w_async_isc_region_{i}_start_address_h (i=0..4) — The ISC Region {i} Start Address High Register defines the start address bits 47 to 32 for the master Ik3_vpu_wave521cl_main_1.pri_m_vbusm_w_async region {i} ISC.
  [15:0] START_ADDRESS_H — Start address bits 47 to 32.
{0x4818+0x20*i} ISC_REGS_Ik3_vpu_wave521cl_main_1_pri_m_vbusm_w_async_isc_region_{i}_end_address_l access per field reset 0xFFF (i=0..4) — The ISC Region {i} End Address Low Register defines the end included address bits 31 to 0 for the master Ik3_vpu_wave521cl_main_1.pri_m_vbusm_w_async region {i} ISC.
  fields as ISC_REGS_Ik3_vpu_wave521cl_main_0_sec_m_vbusm_r_async_isc_region_0_end_address_l
{0x481C+0x20*i} ISC_REGS_Ik3_vpu_wave521cl_main_1_pri_m_vbusm_w_async_isc_region_{i}_end_address_h (i=0..4) — The ISC Region {i} End Address High Register defines the end address bits 47 to 32 for the master Ik3_vpu_wave521cl_main_1.pri_m_vbusm_w_async region {i} ISC.
  [15:0] END_ADDRESS_H — End address bits 47 to 32.
0x48A0 ISC_REGS_Ik3_vpu_wave521cl_main_1_pri_m_vbusm_w_async_isc_region_def_control access not given reset 0xBF4A — The ISC Default Region Control Register defines the control fields for the master Ik3_vpu_wave521cl_main_1.pri_m_vbusm_w_async region 5 ISC.
  fields as ISC_REGS_Ik3_vpu_wave521cl_main_0_sec_m_vbusm_r_async_isc_region_def_control
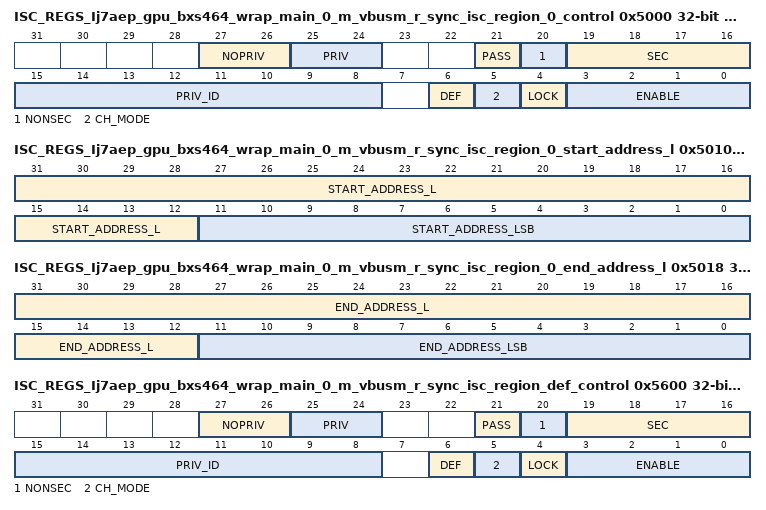
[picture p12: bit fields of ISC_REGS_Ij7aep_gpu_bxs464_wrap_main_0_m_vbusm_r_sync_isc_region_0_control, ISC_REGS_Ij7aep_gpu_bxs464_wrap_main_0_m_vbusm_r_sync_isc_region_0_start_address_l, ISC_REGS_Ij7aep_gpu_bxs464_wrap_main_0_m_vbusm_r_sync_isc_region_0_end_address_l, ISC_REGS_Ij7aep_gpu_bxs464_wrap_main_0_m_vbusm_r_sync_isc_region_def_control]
{0x5000+0x20*i} ISC_REGS_Ij7aep_gpu_bxs464_wrap_main_0_m_vbusm_r_sync_isc_region_{i}_control access not given reset 0xBB00 (i=0..47) — The ISC Region {i} Control Register defines the control fields for the master Ij7aep_gpu_bxs464_wrap_main_0.m_vbusm_r_sync region {i} ISC.
  fields as ISC_REGS_Ik3_vpu_wave521cl_main_0_sec_m_vbusm_r_async_isc_region_0_control
{0x5010+0x20*i} ISC_REGS_Ij7aep_gpu_bxs464_wrap_main_0_m_vbusm_r_sync_isc_region_{i}_start_address_l (i=0..47) — The ISC Region {i} Start Address Low Register defines the start address bits 31 to 0 for the master Ij7aep_gpu_bxs464_wrap_main_0.m_vbusm_r_sync region {i} ISC.
  fields as ISC_REGS_Ik3_vpu_wave521cl_main_0_sec_m_vbusm_r_async_isc_region_0_start_address_l
{0x5014+0x20*i} ISC_REGS_Ij7aep_gpu_bxs464_wrap_main_0_m_vbusm_r_sync_isc_region_{i}_start_address_h (i=0..47) — The ISC Region {i} Start Address High Register defines the start address bits 47 to 32 for the master Ij7aep_gpu_bxs464_wrap_main_0.m_vbusm_r_sync region {i} ISC.
  [15:0] START_ADDRESS_H — Start address bits 47 to 32.
{0x5018+0x20*i} ISC_REGS_Ij7aep_gpu_bxs464_wrap_main_0_m_vbusm_r_sync_isc_region_{i}_end_address_l access per field reset 0xFFF (i=0..47) — The ISC Region {i} End Address Low Register defines the end included address bits 31 to 0 for the master Ij7aep_gpu_bxs464_wrap_main_0.m_vbusm_r_sync region {i} ISC.
  fields as ISC_REGS_Ik3_vpu_wave521cl_main_0_sec_m_vbusm_r_async_isc_region_0_end_address_l
{0x501C+0x20*i} ISC_REGS_Ij7aep_gpu_bxs464_wrap_main_0_m_vbusm_r_sync_isc_region_{i}_end_address_h (i=0..47) — The ISC Region {i} End Address High Register defines the end address bits 47 to 32 for the master Ij7aep_gpu_bxs464_wrap_main_0.m_vbusm_r_sync region {i} ISC.
  [15:0] END_ADDRESS_H — End address bits 47 to 32.
0x5600 ISC_REGS_Ij7aep_gpu_bxs464_wrap_main_0_m_vbusm_r_sync_isc_region_def_control access not given reset 0xBB4A — The ISC Default Region Control Register defines the control fields for the master Ij7aep_gpu_bxs464_wrap_main_0.m_vbusm_r_sync region 48 ISC.
  fields as ISC_REGS_Ik3_vpu_wave521cl_main_0_sec_m_vbusm_r_async_isc_region_def_control
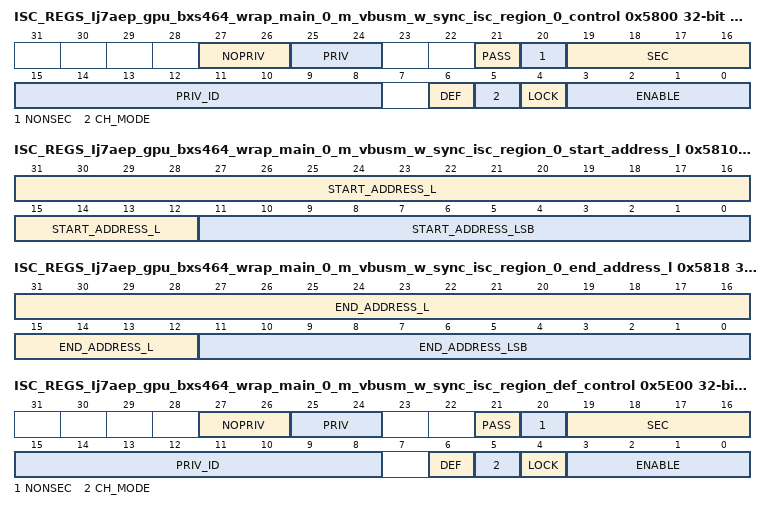
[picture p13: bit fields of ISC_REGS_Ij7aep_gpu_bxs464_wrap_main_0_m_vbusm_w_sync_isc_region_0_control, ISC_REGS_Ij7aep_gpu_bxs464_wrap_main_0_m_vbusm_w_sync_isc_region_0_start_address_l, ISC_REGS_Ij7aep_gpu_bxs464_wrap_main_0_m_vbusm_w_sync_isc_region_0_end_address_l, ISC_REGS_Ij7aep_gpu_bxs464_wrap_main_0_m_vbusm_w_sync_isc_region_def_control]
{0x5800+0x20*i} ISC_REGS_Ij7aep_gpu_bxs464_wrap_main_0_m_vbusm_w_sync_isc_region_{i}_control access not given reset 0xBB00 (i=0..47) — The ISC Region {i} Control Register defines the control fields for the master Ij7aep_gpu_bxs464_wrap_main_0.m_vbusm_w_sync region {i} ISC.
  fields as ISC_REGS_Ik3_vpu_wave521cl_main_0_sec_m_vbusm_r_async_isc_region_0_control
{0x5810+0x20*i} ISC_REGS_Ij7aep_gpu_bxs464_wrap_main_0_m_vbusm_w_sync_isc_region_{i}_start_address_l (i=0..47) — The ISC Region {i} Start Address Low Register defines the start address bits 31 to 0 for the master Ij7aep_gpu_bxs464_wrap_main_0.m_vbusm_w_sync region {i} ISC.
  fields as ISC_REGS_Ik3_vpu_wave521cl_main_0_sec_m_vbusm_r_async_isc_region_0_start_address_l
{0x5814+0x20*i} ISC_REGS_Ij7aep_gpu_bxs464_wrap_main_0_m_vbusm_w_sync_isc_region_{i}_start_address_h (i=0..47) — The ISC Region {i} Start Address High Register defines the start address bits 47 to 32 for the master Ij7aep_gpu_bxs464_wrap_main_0.m_vbusm_w_sync region {i} ISC.
  [15:0] START_ADDRESS_H — Start address bits 47 to 32.
{0x5818+0x20*i} ISC_REGS_Ij7aep_gpu_bxs464_wrap_main_0_m_vbusm_w_sync_isc_region_{i}_end_address_l access per field reset 0xFFF (i=0..47) — The ISC Region {i} End Address Low Register defines the end included address bits 31 to 0 for the master Ij7aep_gpu_bxs464_wrap_main_0.m_vbusm_w_sync region {i} ISC.
  fields as ISC_REGS_Ik3_vpu_wave521cl_main_0_sec_m_vbusm_r_async_isc_region_0_end_address_l
{0x581C+0x20*i} ISC_REGS_Ij7aep_gpu_bxs464_wrap_main_0_m_vbusm_w_sync_isc_region_{i}_end_address_h (i=0..47) — The ISC Region {i} End Address High Register defines the end address bits 47 to 32 for the master Ij7aep_gpu_bxs464_wrap_main_0.m_vbusm_w_sync region {i} ISC.
  [15:0] END_ADDRESS_H — End address bits 47 to 32.
0x5E00 ISC_REGS_Ij7aep_gpu_bxs464_wrap_main_0_m_vbusm_w_sync_isc_region_def_control access not given reset 0xBB4A — The ISC Default Region Control Register defines the control fields for the master Ij7aep_gpu_bxs464_wrap_main_0.m_vbusm_w_sync region 48 ISC.
  fields as ISC_REGS_Ik3_vpu_wave521cl_main_0_sec_m_vbusm_r_async_isc_region_def_control
